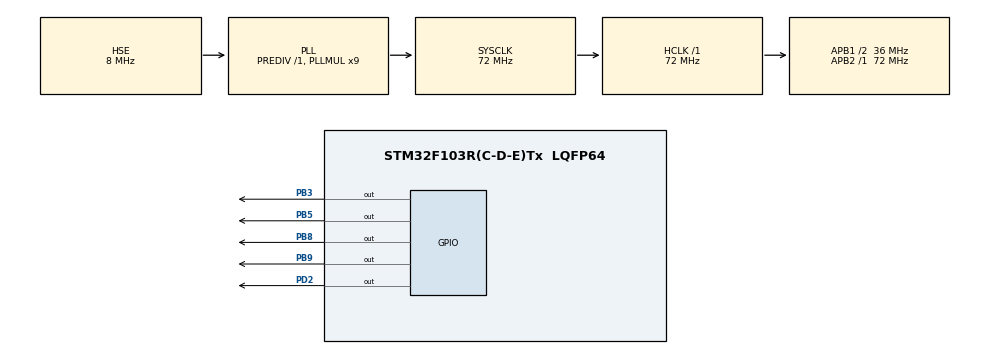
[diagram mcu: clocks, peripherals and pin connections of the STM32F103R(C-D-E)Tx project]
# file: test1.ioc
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Mcu.Family=STM32F1
Mcu.Name=STM32F103R(C-D-E)Tx
Mcu.Package=LQFP64
NVIC.PriorityGroup=NVIC_PRIORITYGROUP_4
PA13.Mode=Serial_Wire
PA13.Signal=SYS_JTMS-SWDIO
PA14.Mode=Serial_Wire
PA14.Signal=SYS_JTCK-SWCLK
PB3.Signal=GPIO_Output
PB5.Signal=GPIO_Output
PB8.Signal=GPIO_Output
PB9.Signal=GPIO_Output
PD0-OSC_IN.Mode=HSE-External-Oscillator
PD0-OSC_IN.Signal=RCC_OSC_IN
PD1-OSC_OUT.Mode=HSE-External-Oscillator
PD1-OSC_OUT.Signal=RCC_OSC_OUT
PD2.Signal=GPIO_Output
ProjectManager.HeapSize=0x200
ProjectManager.StackSize=0x400
ProjectManager.TargetToolchain=EWARM V8.32
RCC.AHBFreq_Value=72000000
RCC.APB1CLKDivider=RCC_HCLK_DIV2
RCC.APB1Freq_Value=36000000
RCC.APB1TimFreq_Value=72000000
RCC.APB2Freq_Value=72000000
RCC.APB2TimFreq_Value=72000000
RCC.EnbaleCSS=true
RCC.HCLKFreq_Value=72000000
RCC.PLLMUL=RCC_PLL_MUL9
RCC.PLLSourceVirtual=RCC_PLLSOURCE_HSE
RCC.SYSCLKFreq_VALUE=72000000
RCC.SYSCLKSource=RCC_SYSCLKSOURCE_PLLCLK
RCC.USBFreq_Value=72000000
board=custom

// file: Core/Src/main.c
/* USER CODE BEGIN Header */
/**
  ******************************************************************************
  * @file           : main.c
  * @brief          : Main program body
  ******************************************************************************
  * @attention
  *
  * <h2><center>&copy; Copyright (c) 2020 STMicroelectronics.
  * All rights reserved.</center></h2>
  *
  * This software component is licensed by ST under BSD 3-Clause license,
  * the "License"; You may not use this file except in compliance with the
  * License. You may obtain a copy of the License at:
  *                        opensource.org/licenses/BSD-3-Clause
  *
  ******************************************************************************
  */
/* USER CODE END Header */
#include "main.h"
#include "gpio.h"

void SystemClock_Config(void);

char word[]={"一个大笨蛋啊"};
int main(void)
{

  /* MCU Configuration--------------------------------------------------------*/

  /* Reset of all peripherals, Initializes the Flash interface and the Systick. */
  HAL_Init();

  /* Configure the system clock */
  SystemClock_Config();

  /* Initialize all configured peripherals */
  MX_GPIO_Init();
  /* USER CODE BEGIN 2 */

  Lcd_Init();
  /* USER CODE END 2 */

  /* Infinite loop */
  /* USER CODE BEGIN WHILE *·/

    /* USER CODE END WHILE */
//uint16_t i
    /* USER CODE BEGIN 3 */
  //  HAL_GPIO_WritePin(GPIOB, GPIO_PIN_8, GPIO_PIN_SET);
  //  Lcd_WriteCmd(0x0c);
while(1)
{
#if(0)
//  LCD_Display_Words(1,1, 'W');
  LCD_SetLoca(1,2);
  LCD_Display_Number(2);
  HAL_Delay(1000);
  Lcd_Clear();
#else
  LCD_Display_Words(0,0,"清时明月汉时关");
  HAL_Delay(3000);
  LCD_Display_Words(1,0,"万里长征人未还");
  LCD_Display_Words(2,0,"但使龙城飞将在");
  LCD_Display_Words(3,0,"不教胡马度阴山");
  HAL_Delay(3000);

#endif
  /* 在这里添加你自己的程序 */

  /*汉字显示*/

  /*汉字显示*/

}
  /* USER CODE END 3 */
}

void SystemClock_Config(void)
{
  RCC_OscInitTypeDef RCC_OscInitStruct = {0};
  RCC_ClkInitTypeDef RCC_ClkInitStruct = {0};

  /** Initializes the RCC Oscillators according to the specified parameters
  * in the RCC_OscInitTypeDef structure.
  */
  RCC_OscInitStruct.OscillatorType = RCC_OSCILLATORTYPE_HSE;
  RCC_OscInitStruct.HSEState = RCC_HSE_ON;
  RCC_OscInitStruct.HSEPredivValue = RCC_HSE_PREDIV_DIV1;
  RCC_OscInitStruct.HSIState = RCC_HSI_ON;
  RCC_OscInitStruct.PLL.PLLState = RCC_PLL_ON;
  RCC_OscInitStruct.PLL.PLLSource = RCC_PLLSOURCE_HSE;
  RCC_OscInitStruct.PLL.PLLMUL = RCC_PLL_MUL9;
  if (HAL_RCC_OscConfig(&RCC_OscInitStruct) != HAL_OK)
  {
    Error_Handler();
  }
  /** Initializes the CPU, AHB and APB buses clocks
  */
  RCC_ClkInitStruct.ClockType = RCC_CLOCKTYPE_HCLK|RCC_CLOCKTYPE_SYSCLK
                              |RCC_CLOCKTYPE_PCLK1|RCC_CLOCKTYPE_PCLK2;
  RCC_ClkInitStruct.SYSCLKSource = RCC_SYSCLKSOURCE_PLLCLK;
  RCC_ClkInitStruct.AHBCLKDivider = RCC_SYSCLK_DIV1;
  RCC_ClkInitStruct.APB1CLKDivider = RCC_HCLK_DIV2;
  RCC_ClkInitStruct.APB2CLKDivider = RCC_HCLK_DIV1;

  if (HAL_RCC_ClockConfig(&RCC_ClkInitStruct, FLASH_LATENCY_2) != HAL_OK)
  {
    Error_Handler();
  }
  /** Enables the Clock Security System
  */
  HAL_RCC_EnableCSS();
}

void Error_Handler(void)
{
}

/************************ (C) COPYRIGHT STMicroelectronics *****END OF FILE****/
